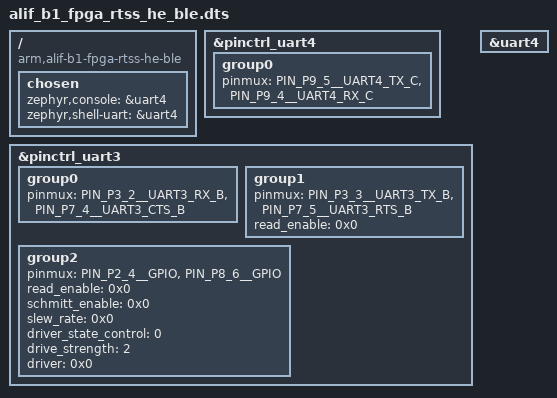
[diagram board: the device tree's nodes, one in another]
/* Copyright (c) 2024 Alif Semiconductor
 *
 * SPDX-License-Identifier: Apache-2.0
 */
/dts-v1/;

#include "alif_b1_fpga_rtss_he.dts"


/ {
	compatible = "arm,alif-b1-fpga-rtss-he-ble";
	#address-cells = <1>;
	#size-cells = <1>;
};

/* Uart4 in FPGA for BLE has different pins connected to output ports */
&pinctrl_uart4 {
	group0 {
		pinmux = <PIN_P9_5__UART4_TX_C>,
		 <PIN_P9_4__UART4_RX_C>;
	};
};

/* Uart3 in defaults FPGA for BLE has Pin conflict with RX pin requiring clearing
 * of the P2-4 and P8-6 pinmux
 */
&pinctrl_uart3 {
	group0 {
		pinmux = <PIN_P3_2__UART3_RX_B>,
			  <PIN_P7_4__UART3_CTS_B>;
	};
	group1 {
		pinmux = <PIN_P3_3__UART3_TX_B>,
			  <PIN_P7_5__UART3_RTS_B>;
		read_enable = <0x0>;
	};
	group2 {
		pinmux = <PIN_P2_4__GPIO>,
			  <PIN_P8_6__GPIO>;
		read_enable = <0x0>;
		schmitt_enable = <0x0>;
		slew_rate = <0x0>;
		driver_state_control = <0>;
		drive_strength = <2>;
		driver = <0x0>;
	};
};

/ {
	chosen {
		zephyr,console = &uart4;
		zephyr,shell-uart = &uart4;
	};
};

&uart4 {
	status = "okay";
};

